VERSION ""

NS_ :

BS_:

BU_: ICM ACC ECM BCM
VAL_TABLE_ BrakeDecAcc 1 "Apply" 0 "DontApply" ;
VAL_TABLE_ ACCState 4 "Fault" 3 "Active" 2 "Standby" 1 "ON" 0 "OFF" ;
VAL_TABLE_ BrakeSwst 1 "Pressed" 0 "notPressed" ;
VAL_TABLE_ CruiseSwstates 7 "None" 6 "TimeGap-" 5 "TimeGap+" 4 "Resume" 3 "Coast" 2 "Set/Accel" 1 "ON" 0 "OFF" ;

BO_ 560 ICMInfo: 8 ICM
 SG_ CruiseSwitchRequest : 1|3@1+ (1,0) [0|0] ""  ACC
 SG_ BrakeSwitch1 : 0|1@1+ (1,0) [0|0] ""  ACC

BO_ 576 BCMInfo: 8 BCM
 SG_ VehicleSpeed : 0|8@1+ (1,0) [0|0] ""  ECM,ACC

BO_ 784 ECMInfo: 8 ECM
 SG_ BrakeSwitch2 : 0|1@1+ (1,0) [0|0] ""  ACC

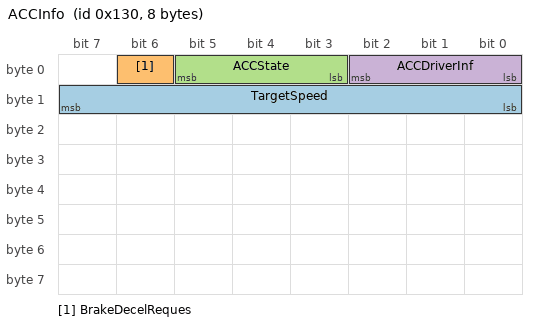
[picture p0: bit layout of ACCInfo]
BO_ 304 ACCInfo: 8 ACC
 SG_ TargetSpeed : 8|8@1+ (1,0) [0|0] "km/h"  ECM
 SG_ BrakeDecelReques : 6|1@1+ (1,0) [0|0] ""  BCM
 SG_ ACCState : 3|3@1+ (1,0) [0|0] ""  ECM,BCM
 SG_ ACCDriverInf : 0|3@1+ (1,0) [0|0] ""  ICM

BA_DEF_ BU_  "ILUsed" ENUM  "No","Yes";
BA_DEF_ BU_  "NodeLayerModules" STRING ;
BA_DEF_ BO_  "GenMsgCycleTime" INT 0 0;
BA_DEF_ BO_  "GenMsgSendType" ENUM  "Cyclic","Event","Event+Cyclic";
BA_DEF_ SG_  "GenSigStartValue" INT 0 0;
BA_DEF_  "BusType" STRING ;
BA_DEF_DEF_  "ILUsed" "Yes";
BA_DEF_DEF_  "NodeLayerModules" "CANoeILNLVector.dll";
BA_DEF_DEF_  "GenMsgCycleTime" 80;
BA_DEF_DEF_  "GenMsgSendType" "Cyclic";
BA_DEF_DEF_  "GenSigStartValue" 0;
BA_DEF_DEF_  "BusType" "CAN";
BA_ "GenMsgCycleTime" BO_ 560 100;
BA_ "GenMsgCycleTime" BO_ 576 150;
BA_ "GenMsgCycleTime" BO_ 784 200;
BA_ "GenMsgCycleTime" BO_ 304 100;
BA_ "GenSigStartValue" SG_ 560 CruiseSwitchRequest 7;
VAL_ 560 CruiseSwitchRequest 7 "None" 6 "TimeGap-" 5 "TimeGap+" 4 "Resume" 3 "Coast" 2 "Set/Accel" 1 "ON" 0 "OFF" ;
VAL_ 560 BrakeSwitch1 1 "Pressed" 0 "notPressed" ;
VAL_ 784 BrakeSwitch2 1 "Pressed" 0 "notPressed" ;
VAL_ 304 BrakeDecelReques 1 "Apply" 0 "DontApply" ;
VAL_ 304 ACCState 4 "Fault" 3 "Active" 2 "Standby" 1 "ON" 0 "OFF" ;
